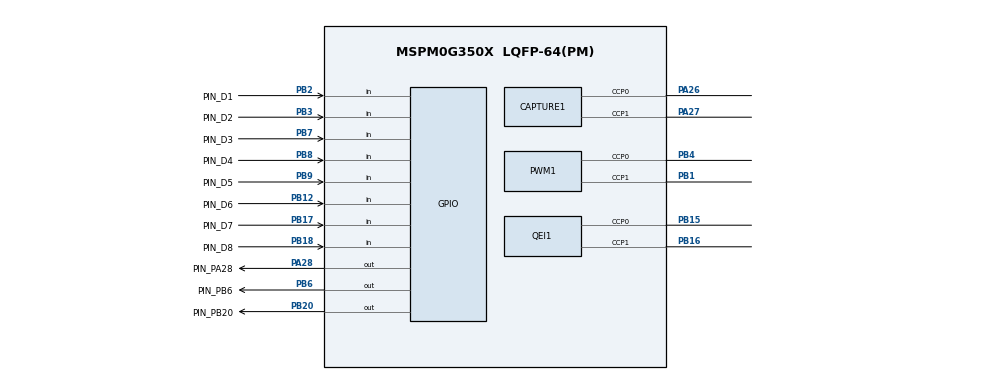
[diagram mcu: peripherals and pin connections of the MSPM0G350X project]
/**
 * @cliArgs --device "MSPM0G350X" --part "Default" --package "LQFP-64(PM)" --product "mspm0_sdk@2.10.00.04"
 * @versions {"tool":"1.26.2+4477"}
 */

/**
 * Import the modules used in this configuration.
 */
const CAPTURE  = scripting.addModule("/ti/driverlib/CAPTURE", {}, false);
const CAPTURE1 = CAPTURE.addInstance();
const GPIO     = scripting.addModule("/ti/driverlib/GPIO", {}, false);
const GPIO1    = GPIO.addInstance();
const GPIO2    = GPIO.addInstance();
const PWM      = scripting.addModule("/ti/driverlib/PWM", {}, false);
const PWM1     = PWM.addInstance();
const QEI      = scripting.addModule("/ti/driverlib/QEI", {}, false);
const QEI1     = QEI.addInstance();
const SYSCTL   = scripting.addModule("/ti/driverlib/SYSCTL");
const SYSTICK  = scripting.addModule("/ti/driverlib/SYSTICK");

/**
 * Write custom configuration values to the imported modules.
 */
CAPTURE1.$name                       = "CAPTURE_RIGHT";
CAPTURE1.captureInputMode            = "multi";
CAPTURE1.ccIndexMulti                = [0,1];
CAPTURE1.multi_ch0_captEdgeDetection = "DL_TIMER_CC_CCOND_TRIG_EDGE";
CAPTURE1.multi_ch1_captEdgeDetection = "DL_TIMER_CC_CCOND_TRIG_EDGE";
CAPTURE1.peripheral.ccp0Pin.$assign  = "PA26";
CAPTURE1.peripheral.ccp1Pin.$assign  = "PA27";
CAPTURE1.ccp0PinConfig.$name         = "ti_driverlib_gpio_GPIOPinGeneric4";
CAPTURE1.ccp1PinConfig.$name         = "ti_driverlib_gpio_GPIOPinGeneric5";

const Board = scripting.addModule("/ti/driverlib/Board", {}, false);

GPIO1.$name                         = "MOTOR_DIR";
GPIO1.associatedPins.create(4);
GPIO1.associatedPins[0].$name       = "PIN_PB13";
GPIO1.associatedPins[1].$name       = "PIN_PB6";
GPIO1.associatedPins[1].pin.$assign = "PB6";
GPIO1.associatedPins[2].$name       = "PIN_PA28";
GPIO1.associatedPins[2].pin.$assign = "PA28";
GPIO1.associatedPins[3].$name       = "PIN_PB20";
GPIO1.associatedPins[3].pin.$assign = "PB20";

GPIO2.$name                         = "TRACKER";
GPIO2.port                          = "PORTB";
GPIO2.associatedPins.create(8);
GPIO2.associatedPins[0].$name       = "PIN_D1";
GPIO2.associatedPins[0].direction   = "INPUT";
GPIO2.associatedPins[0].pin.$assign = "PB2";
GPIO2.associatedPins[1].$name       = "PIN_D2";
GPIO2.associatedPins[1].direction   = "INPUT";
GPIO2.associatedPins[1].pin.$assign = "PB3";
GPIO2.associatedPins[2].$name       = "PIN_D3";
GPIO2.associatedPins[2].direction   = "INPUT";
GPIO2.associatedPins[2].pin.$assign = "PB7";
GPIO2.associatedPins[3].$name       = "PIN_D4";
GPIO2.associatedPins[3].direction   = "INPUT";
GPIO2.associatedPins[3].pin.$assign = "PB8";
GPIO2.associatedPins[4].$name       = "PIN_D5";
GPIO2.associatedPins[4].direction   = "INPUT";
GPIO2.associatedPins[4].pin.$assign = "PB9";
GPIO2.associatedPins[5].$name       = "PIN_D6";
GPIO2.associatedPins[5].direction   = "INPUT";
GPIO2.associatedPins[5].pin.$assign = "PB12";
GPIO2.associatedPins[6].$name       = "PIN_D7";
GPIO2.associatedPins[6].direction   = "INPUT";
GPIO2.associatedPins[6].pin.$assign = "PB17";
GPIO2.associatedPins[7].$name       = "PIN_D8";
GPIO2.associatedPins[7].direction   = "INPUT";
GPIO2.associatedPins[7].pin.$assign = "PB18";

PWM1.$name                              = "PWM_MOTOR";
PWM1.timerCount                         = 800;
PWM1.clockDivider                       = 4;
PWM1.peripheral.ccp0Pin.$assign         = "PB4";
PWM1.peripheral.ccp1Pin.$assign         = "PB1";
PWM1.PWM_CHANNEL_0.$name                = "ti_driverlib_pwm_PWMTimerCC0";
PWM1.PWM_CHANNEL_1.$name                = "ti_driverlib_pwm_PWMTimerCC1";
PWM1.ccp0PinConfig.direction            = scripting.forceWrite("OUTPUT");
PWM1.ccp0PinConfig.hideOutputInversion  = scripting.forceWrite(false);
PWM1.ccp0PinConfig.onlyInternalResistor = scripting.forceWrite(false);
PWM1.ccp0PinConfig.passedPeripheralType = scripting.forceWrite("Digital");
PWM1.ccp0PinConfig.$name                = "ti_driverlib_gpio_GPIOPinGeneric0";
PWM1.ccp1PinConfig.direction            = scripting.forceWrite("OUTPUT");
PWM1.ccp1PinConfig.hideOutputInversion  = scripting.forceWrite(false);
PWM1.ccp1PinConfig.onlyInternalResistor = scripting.forceWrite(false);
PWM1.ccp1PinConfig.passedPeripheralType = scripting.forceWrite("Digital");
PWM1.ccp1PinConfig.$name                = "ti_driverlib_gpio_GPIOPinGeneric1";

QEI1.$name                              = "QEI_LEFT";
QEI1.peripheral.$assign                 = "TIMG8";
QEI1.peripheral.ccp0Pin.$assign         = "PB15";
QEI1.peripheral.ccp1Pin.$assign         = "PB16";
QEI1.ccp0PinConfig.hideOutputInversion  = scripting.forceWrite(false);
QEI1.ccp0PinConfig.onlyInternalResistor = scripting.forceWrite(false);
QEI1.ccp0PinConfig.passedPeripheralType = scripting.forceWrite("Digital");
QEI1.ccp0PinConfig.$name                = "ti_driverlib_gpio_GPIOPinGeneric2";
QEI1.ccp1PinConfig.hideOutputInversion  = scripting.forceWrite(false);
QEI1.ccp1PinConfig.onlyInternalResistor = scripting.forceWrite(false);
QEI1.ccp1PinConfig.passedPeripheralType = scripting.forceWrite("Digital");
QEI1.ccp1PinConfig.$name                = "ti_driverlib_gpio_GPIOPinGeneric3";

SYSCTL.forceDefaultClkConfig = true;

SYSTICK.interruptEnable = true;
SYSTICK.periodEnable    = true;
SYSTICK.period          = 320000;

/**
 * Pinmux solution for unlocked pins/peripherals. This ensures that minor changes to the automatic solver in a future
 * version of the tool will not impact the pinmux you originally saw.  These lines can be completely deleted in order to
 * re-solve from scratch.
 */
CAPTURE1.peripheral.$suggestSolution         = "TIMG7";
Board.peripheral.$suggestSolution            = "DEBUGSS";
Board.peripheral.swclkPin.$suggestSolution   = "PA20";
Board.peripheral.swdioPin.$suggestSolution   = "PA19";
GPIO1.associatedPins[0].pin.$suggestSolution = "PB13";
PWM1.peripheral.$suggestSolution             = "TIMA1";
SYSCTL.peripheral.$suggestSolution           = "SYSCTL";
